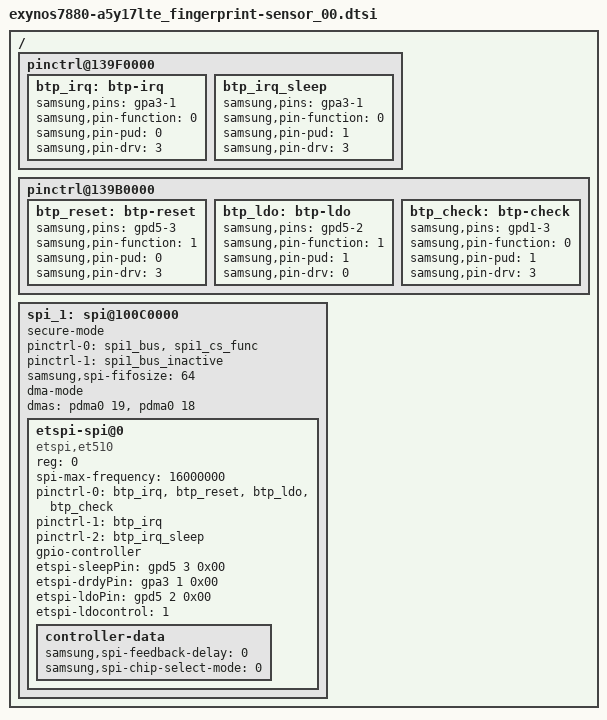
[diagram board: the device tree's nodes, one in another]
/*
 * Copyright (c) 2012-2013, The Linux Foundation. All rights reserved.
 *
 * This program is free software; you can redistribute it and/or modify
 * it under the terms of the GNU General Public License version 2 and
 * only version 2 as published by the Free Software Foundation.
 *
 * This program is distributed in the hope that it will be useful,
 * but WITHOUT ANY WARRANTY; without even the implied warranty of
 * MERCHANTABILITY or FITNESS FOR A PARTICULAR PURPOSE.  See the
 * GNU General Public License for more details.
 */

/ {
	pinctrl@139F0000 {
		btp_irq: btp-irq {
			samsung,pins = "gpa3-1";
			samsung,pin-function = <0>;
			samsung,pin-pud = <0>;
			samsung,pin-drv = <3>;
		};
		btp_irq_sleep: btp_irq_sleep {
			samsung,pins = "gpa3-1";
			samsung,pin-function = <0>;
			samsung,pin-pud = <1>;
			samsung,pin-drv = <3>;
		};
	};

	pinctrl@139B0000 {
		btp_reset: btp-reset {
			samsung,pins = "gpd5-3";
			samsung,pin-function = <1>;
			samsung,pin-pud = <0>;
			samsung,pin-drv = <3>;
		};
		btp_ldo: btp-ldo {
			samsung,pins = "gpd5-2";
			samsung,pin-function = <1>;
			samsung,pin-pud = <1>;
			samsung,pin-drv = <0>;
		};
		btp_check: btp-check {
			samsung,pins = "gpd1-3";
			samsung,pin-function = <0>;
			samsung,pin-pud = <1>;
			samsung,pin-drv = <3>;
		};
	};

	spi_1: spi@100C0000 {
		status = "okay";
		secure-mode;
		#address-cells = <1>;
		#size-cells = <0>;
		pinctrl-names = "default", "idle";
		pinctrl-0 = <&spi1_bus &spi1_cs_func>;
		pinctrl-1 = <&spi1_bus_inactive>;
		samsung,spi-fifosize = <64>;

		dma-mode;
		dmas = <&pdma0 19
			&pdma0 18>;

		dma-names = "tx", "rx";
		etspi-spi@0 {
			compatible = "etspi,et510";
			reg = <0>;
			spi-max-frequency = <16000000>;
			pinctrl-names = "default", "pins_poweron", "pins_poweroff";
			pinctrl-0 = <&btp_irq &btp_reset &btp_ldo &btp_check>;
			pinctrl-1 = <&btp_irq>;
			pinctrl-2 = <&btp_irq_sleep>;

			gpio-controller;
			#gpio-cells = <2>;

			etspi-sleepPin = <&gpd5 3 0x00>;
			etspi-drdyPin = <&gpa3 1 0x00>;
			etspi-ldoPin = <&gpd5 2 0x00>;
			etspi-ldocontrol = <1>;
			controller-data {
				samsung,spi-feedback-delay = <0>;
				samsung,spi-chip-select-mode = <0>;
			};
		};
	};
};
